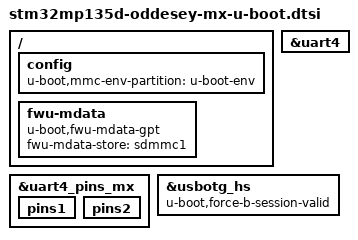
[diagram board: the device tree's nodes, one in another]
// SPDX-License-Identifier: (GPL-2.0-or-later OR BSD-3-Clause)
/*
 * Copyright (C) 2026, STMicroelectronics - All Rights Reserved
 * Author: STM32CubeMX code generation for STMicroelectronics.
 */

/* For more information on Device Tree configuration, please refer to
 * https://wiki.st.com/stm32mpu/wiki/Category:Device_tree_configuration
 */

/* USER CODE BEGIN includes */
/* U-Boot includes only ONE *-u-boot.dtsi: this board file. Pull in the SoC one
 * (bootph tags for rcc, pinctrl, gpio, scmi, ddr...) like ST's DK does. */
#include "stm32mp13-u-boot.dtsi"
/* USER CODE END includes */

/ {

	/* USER CODE BEGIN root */
	config {
		u-boot,mmc-env-partition = "u-boot-env";
	};

	fwu-mdata {
		compatible = "u-boot,fwu-mdata-gpt";
		fwu-mdata-store = <&sdmmc1>;
	};

	/* USER CODE END root */

}; /*root*/

/* USER CODE BEGIN addons */

&uart4 {
	bootph-all;
};

&uart4_pins_mx {
	bootph-all;
	pins1 {
		bootph-all;
	};
	pins2 {
		bootph-all;
	};
};

&usbotg_hs {
	u-boot,force-b-session-valid;
};

/* USER CODE END addons */

